# STM32WBA52 register map
File version: 1.3
CPU: CM33 r0p1, little endian, MPU, FPU, 4 interrupt priority bits
Registers are 32-bit, read-write, reset 0x0 unless marked. A register's access mark holds for its fields unless they carry their own. Offsets are from the block's base; [hi:lo] are bit positions; {n}, {i} and the like mark numbered series.

## GTZC1_MPCBB1 — GTZC1_MPCBB1 address block description
Base 0x40032C00
Same registers: GTZC1_MPCBB2 0x40033000, SEC_GTZC1_MPCBB1 0x50032C00, SEC_GTZC1_MPCBB2 0x50033000
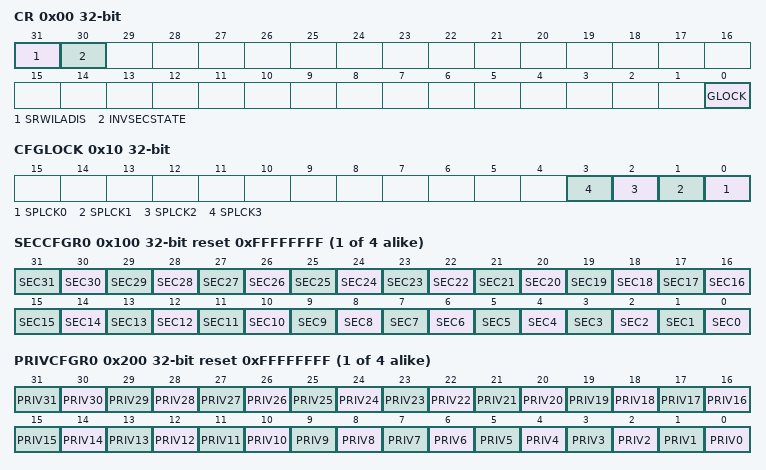
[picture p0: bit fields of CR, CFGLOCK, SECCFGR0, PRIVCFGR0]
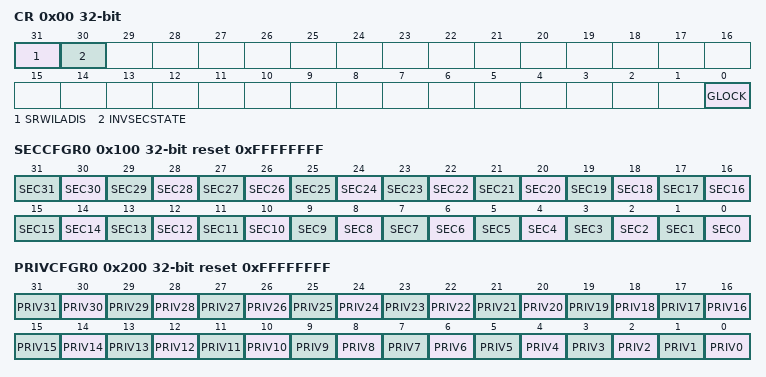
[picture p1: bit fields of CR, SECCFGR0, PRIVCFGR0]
0x00 CR — MPCBB control register
  [31] SRWILADIS — secure read/write illegal access disable; This bit disables the detection of an illegal access when a secure read/write transaction access a non-secure blocks of the block-based SRAM (secure fetch on non-secure block is always considered illegal).
  [30] INVSECSTATE — SRAM clocks security state; This bit is used to define the internal SRAM clocks control in RCC as secure or not.
  [0] GLOCK — lock the control register of the MPCBB until next reset; This bit is cleared by default and once set, it can not be reset until system reset.
0x10 CFGLOCK — GTZC1 SRAMz MPCBB configuration lock register
  [n] SPLCK{n} (n=0..3) — Security/privilege configuration lock super-block; This bit is set by software and can be cleared only by system reset.; note that bit [3:2] are reserved on sales type STM32WBA5xEx for MPCBB1.
{0x100+4i} SECCFGR{i} (i=0..3) reset 0xFFFFFFFF — MPCBBz security configuration for super-block {i} register
  [n] SEC{n} (n=0..31) — Security configuration for block y (y = 0 to 31) in super block n Unprivileged write to this bit is ignored if PRIVy bit is set in GTZC1_MPCBB_PRIVCFGRn. Writes are ignored if SPLCKn bit is set in GTZC1_MPCBB_CFGLOCK.
{0x200+4i} PRIVCFGR{i} (i=0..3) reset 0xFFFFFFFF — MPCBBz privileged configuration for super-block {i} register
  [n] PRIV{n} (n=0..31) — Privileged configuration for block y (y = 0 to 31), belonging to super-block n. Non-secure write to this bit is ignored if SECy bit is set in GTZC1_MPCBB_SECCFGRn. Writes are ignored if SPLCKn bit is set in GTZC1_MPCBB_CFGLOCK.

## GTZC1_MPCBB6 — GTZC1_MPCBB6 address block description
Base 0x40034000
Same registers: SEC_GTZC1_MPCBB6 0x50034000
0x00 CR — MPCBB control register
  [31] SRWILADIS — secure read/write illegal access disable; This bit disables the detection of an illegal access when a secure read/write transaction access a non-secure blocks of the block-based SRAM (secure fetch on non-secure block is always considered illegal).
  [30] INVSECSTATE — SRAM clocks security state; This bit is used to define the internal SRAM clocks control in RCC as secure or not.
  [0] GLOCK — lock the control register of the MPCBB until next reset; This bit is cleared by default and once set, it can not be reset until system reset.
0x10 CFGLOCK — GTZC1 SRAMz MPCBB configuration lock register
  [n] SPLCK{n} (n=0..0) — Security/privilege configuration lock super-block; This bit is set by software and can be cleared only by system reset.; note that bit [3:2] are reserved on sales type STM32WBA5xEx for MPCBB1.
{0x100+4i} SECCFGR{i} (i=0..0) reset 0xFFFFFFFF — MPCBBz security configuration for super-block {i} register
  [n] SEC{n} (n=0..31) — Security configuration for block y (y = 0 to 31) in super block n Unprivileged write to this bit is ignored if PRIVy bit is set in GTZC1_MPCBB_PRIVCFGRn. Writes are ignored if SPLCKn bit is set in GTZC1_MPCBB_CFGLOCK.
{0x200+4i} PRIVCFGR{i} (i=0..0) reset 0xFFFFFFFF — MPCBBz privileged configuration for super-block {i} register
  [n] PRIV{n} (n=0..31) — Privileged configuration for block y (y = 0 to 31), belonging to super-block n. Non-secure write to this bit is ignored if SECy bit is set in GTZC1_MPCBB_SECCFGRn. Writes are ignored if SPLCKn bit is set in GTZC1_MPCBB_CFGLOCK.

## ICACHE — Instruction cache
Base 0x40030400
Same registers: SEC_ICache 0x50030400
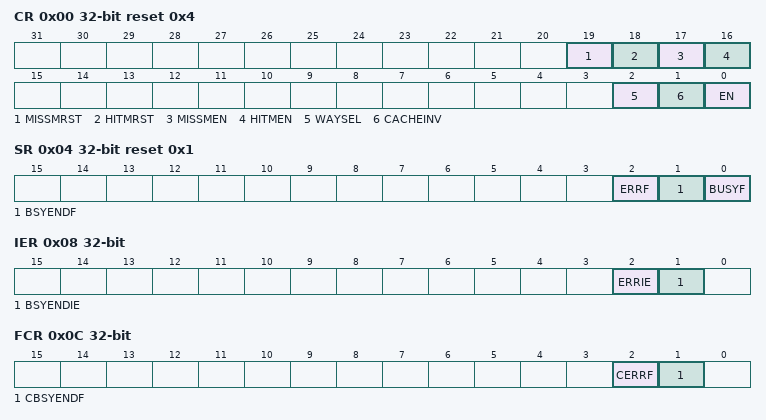
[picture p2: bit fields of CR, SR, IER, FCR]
0x00 CR access per field reset 0x4 — ICACHE control register
  [19] MISSMRST rw — miss monitor reset
  [18] HITMRST rw — hit monitor reset
  [17] MISSMEN rw — miss monitor enable
  [16] HITMEN rw — hit monitor enable
  [2] WAYSEL rw — cache associativity mode selection This bit allows user to choose ICACHE set-associativity. It can be written by software only when cache is disabled (EN=0).
  [1] CACHEINV wo — cache invalidation Set by software and cleared by hardware when the BUSYF flag is set (during cache maintenance operation). Writing 0 has no effect.
  [0] EN rw — enable
0x04 SR ro reset 0x1 — ICACHE status register
  [2] ERRF — cache error flag
  [1] BSYENDF — busy end flag
  [0] BUSYF — busy flag
0x08 IER — ICACHE interrupt enable register
  [2] ERRIE — interrupt enable on cache error Set by software to enable an interrupt generation in case of cache functional error (cacheable write access)
  [1] BSYENDIE — interrupt enable on busy end Set by software to enable an interrupt generation at the end of a cache invalidate operation.
0x0C FCR wo — ICACHE flag clear register
  [2] CERRF — clear cache error flag Set by software.
  [1] CBSYENDF — clear busy end flag Set by software.
0x10 HMONR ro — ICACHE hit monitor register
  [31:0] HITMON — cache hit monitor counter
0x14 MMONR ro — ICACHE miss monitor register
  [15:0] MISSMON — cache miss monitor counter
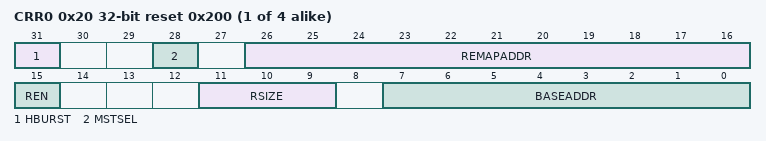
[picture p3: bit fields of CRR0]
{0x20+4i} CRR{i} reset 0x200 (i=0..3) — ICACHE region {i} configuration register
  [31] HBURST — output burst type for region x
  [28] MSTSEL — AHB cache master selection for region x
  [26:16] REMAPADDR — remapped address for region x This field replaces the alias address defined by BASEADDR field. The only useful bits are [31:RI], where 21 less than or equal RI less than or equal 27 is the number of bits of RSIZE (see Section 18.4.7). If the programmed value has more LSBs, the useless bits are ignored.
  [15] REN — enable for region x
  [11:9] RSIZE — size for region x
  [7:0] BASEADDR — base address for region x This alias address is replaced by REMAPADDR field. The only useful bits are [28:RI], where 21 less than or equal RI less than or equal 27 is the number of bits of RSIZE (see Section 18.4.7). If the programmed value has more LSBs, the useless bits are ignored.
